# STM32MP21_CA35 register map
File version: 0.4
CPU: CM33 r0p1, little endian, MPU, FPU, vendor SysTick, 8 interrupt priority bits
Registers are 32-bit, read-write, reset 0x0 unless marked. A register's access mark holds for its fields unless they carry their own. Offsets are from the block's base; [hi:lo] are bit positions; lines under a group give offsets from that group; {n}, {i} and the like mark numbered series; 'fields as' and 'values as' point back to an identical list.

## GICD — GICD address block description
Base 0x4AC10000
Same registers: GICD_S 0x5AC10000
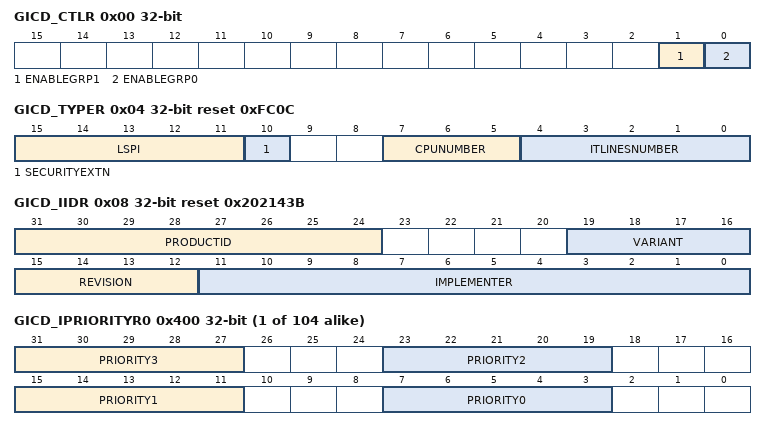
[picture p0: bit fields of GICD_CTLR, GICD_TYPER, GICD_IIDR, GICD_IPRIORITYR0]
0x00 GICD_CTLR — GICD control register
  [1] ENABLEGRP1 — Enable group 1 interrupts
  [0] ENABLEGRP0 — Enable group 0 interrupts
0x00 GICD_CTLRNS (alternate view of GICD_CTLR) — GICD control non-secure access register
  [0] ENABLE — Global enable for forwarding pending group 1 interrupts from the GICD to the CPU interfaces
0x04 GICD_TYPER ro reset 0xFC0C — GICD interrupt controller type register
  [15:11] LSPI — Lockable shared peripheral interrupt
  [10] SECURITYEXTN — Security extension
  [7:5] CPUNUMBER — Number of processor interfaces
  [4:0] ITLINESNUMBER — Number of interrupt lines
0x08 GICD_IIDR ro reset 0x202143B — GICD implementer identification register
  [31:24] PRODUCTID — GIC product ID
  [19:16] VARIANT — GIC major revision number
  [15:12] REVISION — GIC minor revision number
  [11:0] IMPLEMENTER — GIC implementer (0x43B Arm implementation)
{0x80+4i} GICD_IGROUPR{i} (i=0..12) — GICD interrupt group register {i}
  [31:0] IGROUPR{i} — Group x of interrupts
0x100 GICD_ISENABLER0 reset 0xFFFF (reset mask 0xFC00FFFF) — GICD interrupt set-enable register
  [31:0] ISENABLER0 — Interrupt set-enable 0
{0x100+4i} GICD_ISENABLER{i} (i=1..12) — GICD interrupt set-enable register {i}
  [31:0] ISENABLER{i} — Interrupt set-enable x
0x180 GICD_ICENABLER0 reset 0xFFFF (reset mask 0xFC00FFFF) — GICD interrupt clear-enable register
  [31:0] ICENABLER0 — Interrupt clear-enable 0
{0x180+4i} GICD_ICENABLER{i} (i=1..12) — GICD interrupt clear-enable register {i}
  [31:0] ICENABLER{i} — Interrupt clear-enable x
{0x200+4i} GICD_ISPENDR{i} (i=0..12) — GICD interrupt set-pending register {i}
  [31:0] ISPENDR{i} — Interrupt set-pending x
{0x280+4i} GICD_ICPENDR{i} (i=0..12) — GICD interrupt clear-pending register {i}
  [31:0] ICPENDR{i} — Interrupt clear-pending x
{0x300+4i} GICD_ISACTIVER{i} (i=0..12) — GICD interrupt set-active register {i}
  [31:0] ISACTIVER{i} — Interrupt set-active x
{0x380+4i} GICD_ICACTIVER{i} (i=0..12) — GICD interrupt clear-active register {i}
  [31:0] ICACTIVER{i} — Interrupt clear-active x
{0x400+4i} GICD_IPRIORITYR{i} (i=0..103) — GICD interrupt priority register {i}
  [31:27] PRIORITY3 — Priority for interrupt ID = x * 4 + 3
  [23:19] PRIORITY2 — Priority for interrupt ID = x * 4 + 2
  [15:11] PRIORITY1 — Priority for interrupt ID = x * 4 + 1
  [7:3] PRIORITY0 — Priority for interrupt ID = x * 4
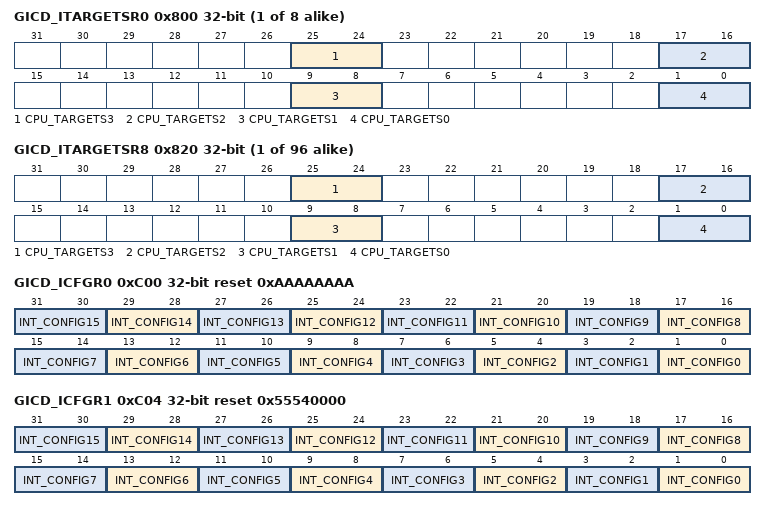
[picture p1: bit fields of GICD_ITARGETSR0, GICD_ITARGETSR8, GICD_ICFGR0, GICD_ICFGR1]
{0x800+4i} GICD_ITARGETSR{i} ro reset not defined (i=0..7) — GICD interrupt processor target register {i}
  [25:24] CPU_TARGETS3 — CPU target for interrupt ID = x * 4 + 3
  [17:16] CPU_TARGETS2 — CPU target for interrupt ID = x * 4 + 2
  [9:8] CPU_TARGETS1 — CPU target for interrupt ID = x * 4 + 1
  [1:0] CPU_TARGETS0 — CPU target for interrupt ID = x * 4
{0x800+4i} GICD_ITARGETSR{i} (i=8..103) — GICD interrupt processor target register {i}
  fields as GICD_ITARGETSR0
0xC00 GICD_ICFGR0 reset 0xAAAAAAAA — GICD interrupt configuration register
  [2n+1:2n] INT_CONFIG{n} (n=0..15) — Interrupt config for interrupt ID = y
0xC04 GICD_ICFGR1 reset 0x55540000 (reset mask 0xFFFC0000) — GICD interrupt configuration register
  [2n+1:2n] INT_CONFIG{n} (n=0..15) — Interrupt config for interrupt ID = y + 16
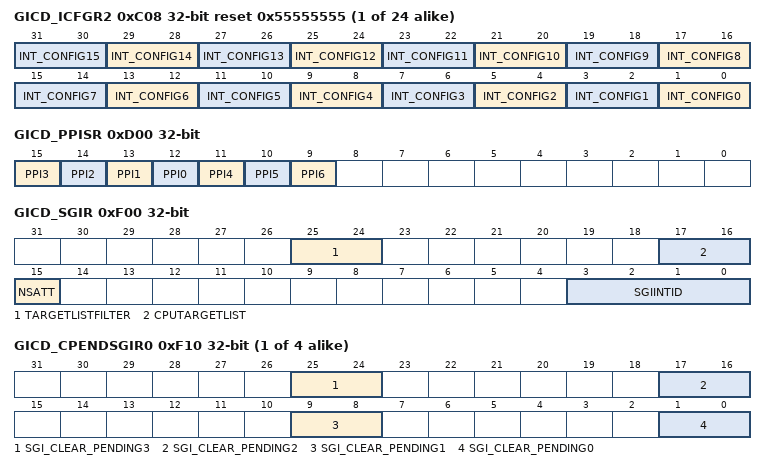
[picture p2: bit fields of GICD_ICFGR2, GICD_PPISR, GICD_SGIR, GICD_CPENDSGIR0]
{0xC00+4i} GICD_ICFGR{i} reset 0x55555555 (i=2..25) — GICD interrupt configuration register {i}
  [2n+1:2n] INT_CONFIG{n} (n=0..15) — Interrupt config for interrupt ID = x * 16 + y
0xD00 GICD_PPISR ro — GICD private peripheral interrupt status register
  [15] PPI3 — nIRQ (not used)
  [14] PPI2 — Secure physical timer event
  [13] PPI1 — Secure physical timer event
  [12] PPI0 — nFIQ (not used)
  [11] PPI4 — Virtual timer event
  [10] PPI5 — Hypervisor timer event
  [9] PPI6 — Virtual maintenance interrupt
{0xD04+4i} GICD_SPISR{i} ro (i=0..11) — GICD shared peripheral interrupt register {i}
  [31:0] SPISR{i} — Shared peripheral x interrupt
0xF00 GICD_SGIR wo reset not defined — GICD software generated interrupt register
  [25:24] TARGETLISTFILTER
    0=Forward the interrupt to the CPU interfaces specified in the CPUTARGETLIST bit field; 1=Forward the interrupt to all CPU interfaces except the processor which requested
  [17:16] CPUTARGETLIST
  [15] NSATT — Non-secure attribute
    0=Forward the SGI specified in the SGIINTID bit field to a specified CPU interface,; 1=Forward the SGI specified in the SGIINTID bit field to a specified CPU interface,
  [3:0] SGIINTID — SGI interrupt ID
{0xF10+4i} GICD_CPENDSGIR{i} (i=0..3) — GICD SGI clear-pending register {i}
  [25:24] SGI_CLEAR_PENDING3 — Clear-pending state for SGI = x * 4 + 3
  [17:16] SGI_CLEAR_PENDING2 — Clear-pending state for SGI = x * 4 + 2
  [9:8] SGI_CLEAR_PENDING1 — Clear-pending state for SGI = x * 4 + 1
  [1:0] SGI_CLEAR_PENDING0 — Clear-pending state for SGI = x * 4
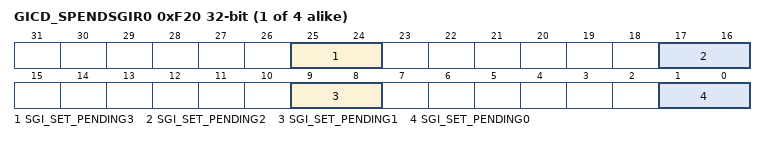
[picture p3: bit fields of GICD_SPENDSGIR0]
{0xF20+4i} GICD_SPENDSGIR{i} (i=0..3) — GICD SGI set-pending register {i}
  [25:24] SGI_SET_PENDING3 — Set-pending state for SGI = x * 4 + 3
  [17:16] SGI_SET_PENDING2 — Set-pending state for SGI= x * 4 + 2
  [9:8] SGI_SET_PENDING1 — Set-pending state for SGI = x * 4 + 1
  [1:0] SGI_SET_PENDING0 — Set-pending state for SGI = x * 4
0xFD0 GICD_PIDR4 ro reset 0x4 — GICD peripheral ID4 register
  [31:0] PIDR4 — Peripheral ID4
{0xFC0+4i} GICD_PIDR{i} ro (i=5..7) — GICD peripheral ID5 to ID7 register {i}
  [31:0] PIDR{i} — Peripheral ID x
0xFE0 GICD_PIDR0 ro reset 0x90 — GICD peripheral ID0 register
  [31:0] PIDR0 — Peripheral ID0
0xFE4 GICD_PIDR1 ro reset 0xB4 — GICD peripheral ID1 register
  [31:0] PIDR1 — Peripheral ID1
0xFE8 GICD_PIDR2 ro reset 0x2B — GICD peripheral ID2 register
  [31:0] PIDR2 — Peripheral ID2
0xFEC GICD_PIDR3 ro — GICD peripheral ID3 register
  [31:0] PIDR3 — Peripheral ID3
0xFF0 GICD_CIDR0 ro reset 0xD — GICD component ID0 register
  [31:0] CIDR0 — Component ID0
0xFF4 GICD_CIDR1 ro reset 0xF0 — GICD component ID1 register
  [31:0] CIDR1 — Component ID1
0xFF8 GICD_CIDR2 ro reset 0x5 — GICD component ID2 register
  [31:0] CIDR2 — Component ID2
0xFFC GICD_CIDR3 ro reset 0xB1 — GICD component ID3 register
  [31:0] CIDR3 — Component ID3
